# STM32WBA55 register map
File version: 1.0
CPU: CM33 r0p1, little endian, MPU, FPU, 4 interrupt priority bits
Registers are 32-bit, read-write, reset 0x0 unless marked. A register's access mark holds for its fields unless they carry their own. Offsets are from the block's base; [hi:lo] are bit positions; {n}, {i} and the like mark numbered series.

## EXTI — External interrupt/event controller
Base 0x46022000
Same registers: SEC_EXTI 0x56022000
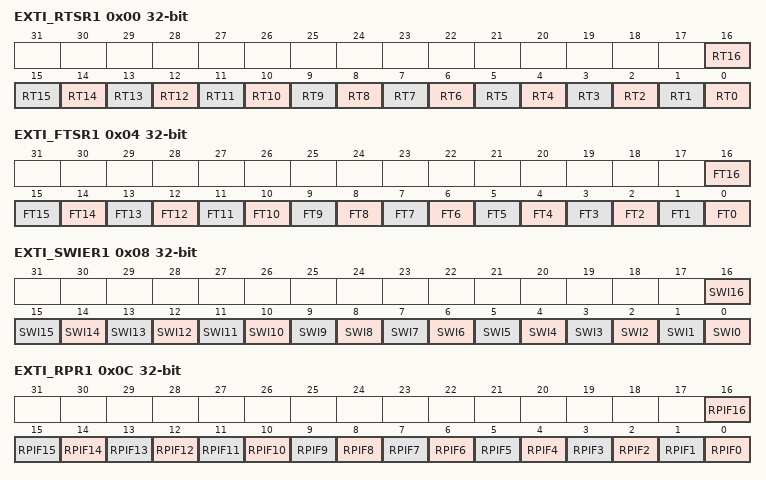
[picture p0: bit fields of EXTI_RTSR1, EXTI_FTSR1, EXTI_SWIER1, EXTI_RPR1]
0x00 EXTI_RTSR1 — EXTI rising trigger selection register
  [all] fields
    0=Rising trigger disabled (for event and interrupt) for input line; 1=Rising trigger enabled (for event and interrupt) for input line
  [n] RT{n} (n=0..16) — Rising trigger event configuration bit of configurable event input x When EXTI_SECCFGR.SECx is disabled, RTx can be accessed with non-secure and secure access. When EXTI_SECCFGR.SECx is enabled, RTx can only be accessed with secure access. Non-secure write to this bit x is discarded and non-secure read returns 0. When EXTI_PRIVCFGR.PRIVx is disabled, RTx can be accessed with unprivileged and privileged access. When EXTI_PRIVCFGR.PRIVx is enabled, RTx can only be accessed with privileged access. Unprivileged write to this bit x is discarded, unprivileged read returns 0.
0x04 EXTI_FTSR1 — EXTI falling trigger selection register
  [all] fields
    0=Falling trigger disabled (for event and Interrupt) for input line; 1=Falling trigger enabled (for event and Interrupt) for input line
  [n] FT{n} (n=0..16) — Falling trigger event configuration bit of configurable event input x When EXTI_SECCFGR.SECx is disabled, FTx can be accessed with non-secure and secure access. When EXTI_SECCFGR.SECx is enabled, FTx can only be accessed with secure access. Non-secure write to this FTx is discarded, non-secure read returns 0. When EXTI_PRIVCFGR.PRIVx is disabled, FTx can be accessed with unprivileged and privileged access. When EXTI_PRIVCFGR.PRIVx is enabled, FTx can only be accessed with privileged access. Unprivileged write to this FTx is discarded, unprivileged read returns 0.
0x08 EXTI_SWIER1 — EXTI software interrupt event register
  [all] fields
    0=Writing 0 has no effect; 1=Writing 1 triggers a rising edge event on event x. This bit is auto cleared by hardware.
  [n] SWI{n} (n=0..16) — Software interrupt on event x When EXTI_SECFGR.SECx is disabled, SWIx can be accessed with non-secure and secure access. When EXTI_SECCFGR.SECx is enabled, SWIx can only be accessed with secure access. Non-secure write to this SWI x is discarded, non-secure read returns 0. When EXTI_PRIVCFGR.PRIVx is disabled, SWIx can be accessed with unprivileged and privileged access. When EXTI_PRIVCFGR.PRIVx is enabled, SWIx can only be accessed with privileged access. Unprivileged write to this SWIx is discarded, unprivileged read returns 0. A software interrupt is generated independently from the setting in EXTI_RTSR and EXTI_FTSR. It always returns 0 when read.
0x0C EXTI_RPR1 — EXTI rising edge pending register
  [all] fields
    0=No rising edge trigger request occurred; 1=Rising edge trigger request occurred
  [n] RPIF{n} (n=0..16) — configurable event inputs x rising edge pending bit When EXTI_SECCFGR.SECx is disabled, RPIFx can be accessed with non-secure and secure access. When EXTI_SECCFGR.SECx is enabled, RPIFx can only be accessed with secure access. Non-secure write to this RPIFx is discarded, non-secure read returns 0. When EXTI_PRIVCFGR.PRIVx is disabled, RPIFx can be accessed with unprivileged and privileged access. When EXTI_PRIVCFGR.PRIVx is enabled, RPIFx can only be accessed with privileged access. Unprivileged write to this RPIFx is discarded, unprivileged read returns 0. This bit is set when the rising edge event or an EXTI_SWIER software trigger arrives on the configurable event line. This bit is cleared by writing 1 to it.
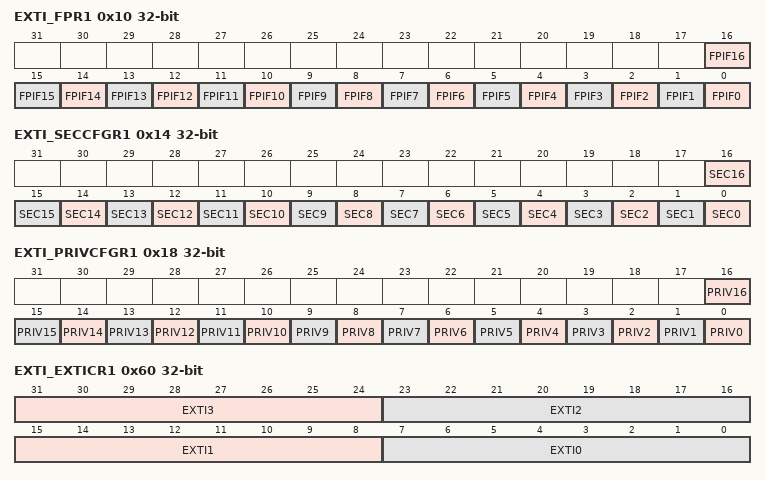
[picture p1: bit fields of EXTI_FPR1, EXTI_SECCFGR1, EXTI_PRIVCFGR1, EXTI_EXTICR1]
0x10 EXTI_FPR1 — EXTI falling edge pending register
  [all] fields
    0=No falling edge trigger request occurred; 1=Falling edge trigger request occurred
  [n] FPIF{n} (n=0..16) — configurable event inputs x falling edge pending bit When EXTI_SECCFGR.SECx is disabled, FPIFx can be accessed with non-secure and secure access. When EXTI_SECCFGR.SECx is enabled, FPIFx can only be accessed with secure access. Non-secure write to this FPIFx is discarded, non-secure read returns 0. When EXTI_PRIVCFGR.PRIVx is disabled, FPIFx can be accessed with unprivileged and privileged access. When EXTI_PRIVCFGR.PRIVx is enabled, FPIFx can only be accessed with privileged access. Unprivileged write to this FPIFx is discarded, unprivileged read returns 0. This bit is set when the falling edge event arrives on the configurable event line. This bit is cleared by writing 1 to it.
0x14 EXTI_SECCFGR1 — EXTI security configuration register
  [all] fields
    0=Event security disabled (non-secure); 1=Event security enabled (secure)
  [n] SEC{n} (n=0..16) — Security enable on event input x When EXTI_PRIVCFGR.PRIVx is disabled, SECx can be accessed with privileged and unprivileged access. When EXTI_PRIVCFGR.PRIVx is enabled, SECx can only be written with privileged access. Unprivileged write to this SECx is discarded.
0x18 EXTI_PRIVCFGR1 — EXTI privilege configuration register
  [all] fields
    0=Event privilege disabled (unprivileged); 1=Event privilege enabled (privileged)
  [n] PRIV{n} (n=0..16) — Security enable on event input x When EXTI_SECCFGR.SECx is disabled, PRIVx can be accessed with secure and non-secure access. When EXTI_SECCFGR.SECx is enabled, PRIVx can only be written with secure access. Non-secure write to this PRIVx is discarded.
0x60 EXTI_EXTICR1 — EXTI external interrupt selection register
  [31:24] EXTI3 — EXTI3 GPIO port selection These bits are written by software to select the source input for EXTI3 external interrupt. When EXTI_SECCFGR.SEC3 is disabled, EXTI3 can be accessed with non-secure and secure access. When EXTI_SECCFGR.SEC3 is enabled, EXTI3 can only be accessed with secure access. Non-secure write is discarded and non-secure read returns 0. When EXTI_PRIVCFGR.PRIV3 is disabled, EXTI3 can be accessed with privileged and unprivileged access. When EXTI_PRIVCFGR.PRIV3 is enabled, EXTI3 can only be accessed with privileged access. Unprivileged write to this bit is discarded. Others: reserved
    0=PA3 pin; 1=PB3 pin; 7=PH3 pin
  [23:16] EXTI2 — EXTI2 GPIO port selection These bits are written by software to select the source input for EXTI2 external interrupt. When EXTI_SECCFGR.SEC2 is disabled, EXTI2 can be accessed with non-secure and secure access. When EXTI_SECCFGR.SEC2 is enabled, EXTI2 can only be accessed with secure access. Non-secure write is discarded and non-secure read returns 0. When EXTI_PRIVCFGR.PRIV2 is disabled, EXTI2 can be accessed with privileged and unprivileged access. When EXTI_PRIVCFGR.PRIV2 is enabled, EXTI2 can only be accessed with privileged access. Unprivileged write to this bit is discarded. Others: reserved
    0=PA2 pin; 1=PB2 pin
  [15:8] EXTI1 — EXTI1 GPIO port selection These bits are written by software to select the source input for EXTI1 external interrupt. When EXTI_SECCFGR.SEC1 is disabled, EXTI1 can be accessed with non-secure and secure access. When EXTI_SECCFGR.SEC1 is enabled, EXTI1 can only be accessed with secure access. Non-secure write is discarded and non-secure read returns 0. When EXTI_PRIVCFGR.PRIV1 is disabled, EXTI1 can be accessed with privileged and unprivileged access. When EXTI_PRIVCFGR.PRIV1 is enabled, EXTI1 can only be accessed with privileged access. Unprivileged write to this bit is discarded. Others: reserved
    0=PA1 pin; 1=PB1 pin
  [7:0] EXTI0 — EXTI0 GPIO port selection These bits are written by software to select the source input for EXTI0 external interrupt. When EXTI_SECCFGR.SEC0 is disabled, EXTI0 can be accessed with non-secure and secure access. When EXTI_SECCFGR.SEC0 is enabled, EXTI0 can only be accessed with secure access. Non-secure write is discarded and non-secure read returns 0. When EXTI_PRIVCFGR.PRIV0 is disabled, EXTI0 can be accessed with privileged and unprivileged access. When EXTI_PRIVCFGR.PRIV0 is enabled, EXTI0 can only be accessed with privileged access. Unprivileged write to this bit is discarded. Others: reserved
    0=PA0 pin; 1=PB0 pin
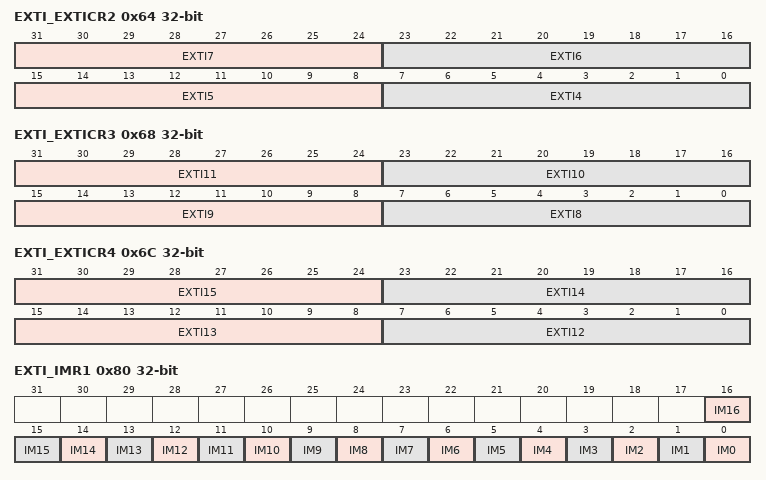
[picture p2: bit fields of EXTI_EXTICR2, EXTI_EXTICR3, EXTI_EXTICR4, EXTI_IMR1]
0x64 EXTI_EXTICR2 — EXTI external interrupt selection register
  [31:24] EXTI7 — EXTI7 GPIO port selection These bits are written by software to select the source input for EXTI7 external interrupt. When EXTI_SECCFGR.SEC7 is disabled, EXTI7 can be accessed with non-secure and secure access. When EXTI_SECCFGR.SEC7 is enabled, EXTI7 can only be accessed with secure access. Non-secure write is discarded and non-secure read returns 0. When EXTI_PRIVCFGR.PRIV7 is disabled, EXTI7 can be accessed with privileged and unprivileged access. When EXTI_PRIVCFGR.PRIV7 is enabled, EXTI7 can only be accessed with privileged access. Unprivileged write to this bit is discarded. Others: reserved
    0=PA7 pin; 1=PB7 pin
  [23:16] EXTI6 — EXTI6 GPIO port selection These bits are written by software to select the source input for EXTI6 external interrupt. When EXTI_SECCFGR.SEC6 is disabled, EXTI6 can be accessed with non-secure and secure access. When EXTI_SECCFGR.SEC6 is enabled, EXTI6 can only be accessed with secure access. Non-secure write is discarded and non-secure read returns 0. When EXTI_PRIVCFGR.PRIV6 is disabled, EXTI6 can be accessed with privileged and unprivileged access. When EXTI_PRIVCFGR.PRIV6 is enabled, EXTI6 can only be accessed with privileged access. Unprivileged write to this bit is discarded. Others: reserved
    0=PA6 pin; 1=PB6 pin
  [15:8] EXTI5 — EXTI5 GPIO port selection These bits are written by software to select the source input for EXTI5 external interrupt. When EXTI_SECCFGR.SEC5 is disabled, EXTI5 can be accessed with non-secure and secure access. When EXTI_SECCFGR.SEC5 is enabled, EXTI5 can only be accessed with secure access. Non-secure write is discarded and non-secure read returns 0. When EXTI_PRIVCFGR.PRIV5 is disabled, EXTI5 can be accessed with privileged and unprivileged access. When EXTI_PRIVCFGR.PRIV5 is enabled, EXTI5 can only be accessed with privileged access. Unprivileged write to this bit is discarded. Others: reserved
    0=PA5 pin; 1=PB5 pin
  [7:0] EXTI4 — EXTI4 GPIO port selection These bits are written by software to select the source input for EXTI4 external interrupt. When EXTI_SECCFGR.SEC4 is disabled, EXTI4 can be accessed with non-secure and secure access. When EXTI_SECCFGR.SEC4 is enabled, EXTI4 can only be accessed with secure access. Non-secure write is discarded and non-secure read returns 0. When EXTI_PRIVCFGR.PRIV4 is disabled, EXTI4 can be accessed with privileged and unprivileged access. When EXTI_PRIVCFGR.PRIV4 is enabled, EXTI4 can only be accessed with privileged access. Unprivileged write to this bit is discarded. Others: reserved
    0=No port pin selected; 1=PB4 pin
0x68 EXTI_EXTICR3 — EXTI external interrupt selection register
  [31:24] EXTI11 — EXTI11 GPIO port selection These bits are written by software to select the source input for EXTI11 external interrupt. When EXTI_SECCFGR.SEC11 is disabled, EXTI11 can be accessed with non-secure and secure access. When EXTI_SECCFGR.SEC11 is enabled, EXTI11 can only be accessed with secure access. Non-secure write is discarded and non-secure read returns 0. When EXTI_PRIVCFGR.PRIV11 is disabled, EXTI11 can be accessed with privileged and unprivileged access. When EXTI_PRIVCFGR.PRIV11 is enabled, EXTI11 can only be accessed with privileged access. Unprivileged write to this bit is discarded. Others: reserved
    0=PA11 pin; 1=PB11 pin
  [23:16] EXTI10 — EXTI10 GPIO port selection These bits are written by software to select the source input for EXTI10 external interrupt. When EXTI_SECCFGR.SEC10 is disabled, EXTI10 can be accessed with non-secure and secure access. When EXTI_SECCFGR.SEC10 is enabled, EXTI10 can only be accessed with secure access. Non-secure write is discarded and non-secure read returns 0. When EXTI_PRIVCFGR.PRIV10 is disabled, EXTI10 can be accessed with privileged and unprivileged access. When EXTI_PRIVCFGR.PRIV10 is enabled, EXTI10 can only be accessed with privileged access. Unprivileged write to this bit is discarded. Others: reserved
    0=PA10 pin; 1=PB10 pin (reserved on STM32WBA55xx devices)
  [15:8] EXTI9 — EXTI9 GPIO port selection These bits are written by software to select the source input for EXTI9 external interrupt. When EXTI_SECCFGR.SEC9 is disabled, EXTI9 can be accessed with non-secure and secure access. When EXTI_SECCFGR.SEC9 is enabled, EXTI9 can only be accessed with secure access. Non-secure write is discarded and non-secure read returns 0. When EXTI_PRIVCFGR.PRIV9 is disabled, EXTI9 can be accessed with privileged and unprivileged access. When EXTI_PRIVCFGR.PRIV9 is enabled, EXTI9 can only be accessed with privileged access. Unprivileged write to this bit is discarded. Others: reserved
    0=PA9 pin; 1=PB9 pin
  [7:0] EXTI8 — EXTI8 GPIO port selection These bits are written by software to select the source input for EXTI8 external interrupt. When EXTI_SECCFGR.SEC8 is disabled, EXTI8 can be accessed with non-secure and secure access. When EXTI_SECCFGR.SEC8 is enabled, EXTI8 can only be accessed with secure access. Non-secure write is discarded and non-secure read returns 0. When EXTI_PRIVCFGR.PRIV8 is disabled, EXTI8 can be accessed with privileged and unprivileged access. When EXTI_PRIVCFGR.PRIV8 is enabled, EXTI8 can only be accessed with privileged access. Unprivileged write to this bit is discarded. Others: reserved
    0=PA8 pin; 1=PB8 pin
0x6C EXTI_EXTICR4 — EXTI external interrupt selection register
  [31:24] EXTI15 — EXTI15 GPIO port selection These bits are written by software to select the source input for EXTI15 external interrupt. When EXTI_SECCFGR.SEC15 is disabled, EXTI15 can be accessed with non-secure and secure access. When EXTI_SECCFGR.SEC15 is enabled, EXTI15 can only be accessed with secure access. Non-secure write is discarded and non-secure read returns 0. When EXTI_PRIVCFGR.PRIV15 is disabled, EXTI15 can be accessed with privileged and unprivileged access. When EXTI_PRIVCFGR.PRIV15 is enabled, EXTI15 can only be accessed with privileged access. Unprivileged write to this bit is discarded. Others: reserved
    0=PA15 pin; 1=PB15 pin; 2=PC15 pin
  [23:16] EXTI14 — EXTI14 GPIO port selection These bits are written by software to select the source input for EXTI14 external interrupt. When EXTI_SECCFGR.SEC14 is disabled, EXTI14 can be accessed with non-secure and secure access. When EXTI_SECCFGR.SEC14 is enabled, EXTI14 can only be accessed with secure access. Non-secure write is discarded and non-secure read returns 0. When EXTI_PRIVCFGR.PRIV14 is disabled, EXTI14 can be accessed with privileged and unprivileged access. When EXTI_PRIVCFGR.PRIV14 is enabled, EXTI14 can only be accessed with privileged access. Unprivileged write to this bit is discarded. Others: reserved
    0=PA14 pin; 1=PB14 pin; 2=PC14 pin
  [15:8] EXTI13 — EXTI13 GPIO port selection These bits are written by software to select the source input for EXTI13 external interrupt. When EXTI_SECCFGR.SEC13 is disabled, EXTI13 can be accessed with non-secure and secure access. When EXTI_SECCFGR.SEC13 is enabled, EXTI13 can only be accessed with secure access. Non-secure write is discarded and non-secure read returns 0. When EXTI_PRIVCFGR.PRIV13 is disabled, EXTI13 can be accessed with privileged and unprivileged access. When EXTI_PRIVCFGR.PRIV13 is enabled, EXTI13 can only be accessed with privileged access. Unprivileged write to this bit is discarded. Others: reserved
    0=PA13 pin; 1=PB13 pin; 2=PC13 pin
  [7:0] EXTI12 — EXTI0 GPIO port selection These bits are written by software to select the source input for EXTI12 external interrupt. When EXTI_SECCFGR.SEC12 is disabled, EXTI12 can be accessed with non-secure and secure access. When EXTI_SECCFGR.SEC12 is enabled, EXTI12 can only be accessed with secure access. Non-secure write is discarded and non-secure read returns 0. When EXTI_PRIVCFGR.PRIV12 is disabled, EXTI12 can be accessed with privileged and unprivileged access. When EXTI_PRIVCFGR.PRIV12 is enabled, EXTI12 can only be accessed with privileged access. Unprivileged write to this bit is discarded. Others: reserved
    0=PA12 pin; 1=PB12 pin
0x70 EXTI_LOCKR — EXTI lock register
  [0] LOCK — Global security and privilege configuration registers (EXTI_SECCFGR and EXTI_PRIVCFGR) lock This bit is written once after reset.
    0=Security and privilege configuration open, can be modified; 1=Security and privilege configuration locked, can no longer be modified
0x80 EXTI_IMR1 — EXTI CPU wakeup with interrupt mask register
  [all] fields
    0=Wakeup with interrupt request from input event x is masked; 1=Wakeup with interrupt request from input event x is unmasked
  [n] IM{n} (n=0..16) — CPU wakeup with interrupt mask on event input x When EXTI_SECCFGR.SECx is disabled, IMx can be accessed with non-secure and secure access. When EXTI_SECCFGR.SECx is enabled, IMx can only be accessed with secure access. Non-secure write to this bit is discarded and non-secure read returns 0. When EXTI_PRIVCFGR.PRIVx is disabled, IMx can be accessed with privileged and unprivileged access. When EXTI_PRIVCFGR.PRIVx is enabled, IMx can only be accessed with privileged access. Unprivileged write to this bit is discarded.
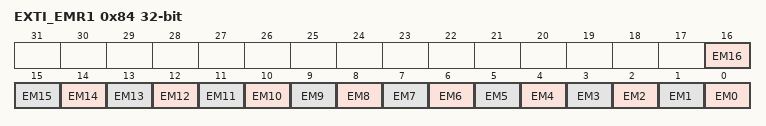
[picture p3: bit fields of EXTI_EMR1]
0x84 EXTI_EMR1 — EXTI CPU wakeup with event mask register
  [all] fields
    0=Wakeup with event generation from Line x is masked; 1=Wakeup with event generation from Line x is unmasked
  [n] EM{n} (n=0..16) — CPU wakeup with event generation mask on event input x When EXTI_SECCFGR.SECx is disabled, EMx can be accessed with non-secure and secure access. When EXTI_SECCFGR.SECx is enabled, EMx can only be accessed with secure access. Non-secure write to this bit x is discarded and non-secure read returns 0. When EXTI_PRIVCFGR.PRIVx is disabled, EMx can be accessed with privileged and unprivileged access. When EXTI_PRIVCFGR.PRIVx is enabled, EMx can only be accessed with privileged access. Unprivileged write to this bit is discarded.

## Notices in the file
Copyright (c) 2025 STMicroelectronics.
SPDX-License-Identifier: Apache-2.0
Licensed under the Apache License, Version 2.0 (the "License");
you may not use this file except in compliance with the License.
You may obtain a copy of the License at
http://www.apache.org/licenses/LICENSE-2.0
Unless required by applicable law or agreed to in writing, software
distributed under the License is distributed on an "AS IS" BASIS,
WITHOUT WARRANTIES OR CONDITIONS OF ANY KIND, either express or implied.
See the License for the specific language governing permissions and
limitations under the License.
